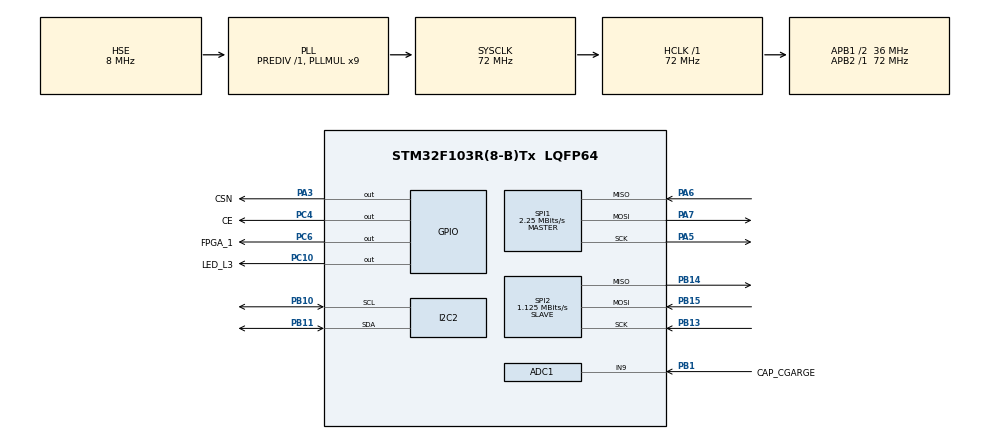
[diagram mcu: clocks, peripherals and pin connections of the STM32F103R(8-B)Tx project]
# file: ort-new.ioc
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ADC1.Channel-8\#ChannelRegularConversion=ADC_CHANNEL_9
ADC1.NbrOfConversionFlag=1
ADC1.Rank-8\#ChannelRegularConversion=1
ADC1.SamplingTime-8\#ChannelRegularConversion=ADC_SAMPLETIME_1CYCLE_5
ADC1.master=1
I2C2.I2C_Mode=I2C_Fast
Mcu.Family=STM32F1
Mcu.Name=STM32F103R(8-B)Tx
Mcu.Package=LQFP64
NVIC.ADC1_2_IRQn=true\:0\:0\:false\:false\:true\:true\:true
NVIC.PriorityGroup=NVIC_PRIORITYGROUP_4
PA13.Mode=Serial_Wire
PA13.Signal=SYS_JTMS-SWDIO
PA14.Mode=Serial_Wire
PA14.Signal=SYS_JTCK-SWCLK
PA3.GPIO_Label=CSN
PA3.Signal=GPIO_Output
PA5.Mode=Full_Duplex_Master
PA5.Signal=SPI1_SCK
PA6.Mode=Full_Duplex_Master
PA6.Signal=SPI1_MISO
PA7.Mode=Full_Duplex_Master
PA7.Signal=SPI1_MOSI
PB1.GPIO_Label=CAP_CGARGE
PB1.Signal=ADCx_IN9
PB10.Mode=I2C
PB10.Signal=I2C2_SCL
PB11.Mode=I2C
PB11.Signal=I2C2_SDA
PB13.Mode=Full_Duplex_Slave
PB13.Signal=SPI2_SCK
PB14.Mode=Full_Duplex_Slave
PB14.Signal=SPI2_MISO
PB15.Mode=Full_Duplex_Slave
PB15.Signal=SPI2_MOSI
PC10.GPIO_Label=LED_L3
PC10.Signal=GPIO_Output
PC14-OSC32_IN.Mode=LSE-External-Oscillator
PC14-OSC32_IN.Signal=RCC_OSC32_IN
PC15-OSC32_OUT.Mode=LSE-External-Oscillator
PC15-OSC32_OUT.Signal=RCC_OSC32_OUT
PC4.GPIO_Label=CE
PC4.Signal=GPIO_Output
PC6.GPIO_Label=FPGA_1
PC6.Signal=GPIO_Output
PD0-OSC_IN.Mode=HSE-External-Oscillator
PD0-OSC_IN.Signal=RCC_OSC_IN
PD1-OSC_OUT.Mode=HSE-External-Oscillator
PD1-OSC_OUT.Signal=RCC_OSC_OUT
ProjectManager.HeapSize=0x200
ProjectManager.StackSize=0x400
ProjectManager.TargetToolchain=MDK-ARM V5
RCC.ADCPresc=RCC_ADCPCLK2_DIV6
RCC.AHBFreq_Value=72000000
RCC.APB1CLKDivider=RCC_HCLK_DIV2
RCC.APB1Freq_Value=36000000
RCC.APB1TimFreq_Value=72000000
RCC.APB2Freq_Value=72000000
RCC.APB2TimFreq_Value=72000000
RCC.HCLKFreq_Value=72000000
RCC.PLLMUL=RCC_PLL_MUL9
RCC.PLLSourceVirtual=RCC_PLLSOURCE_HSE
RCC.PREFETCH_ENABLE=1
RCC.SYSCLKFreq_VALUE=72000000
RCC.SYSCLKSource=RCC_SYSCLKSOURCE_PLLCLK
RCC.TimSys_Div=SYSTICK_CLKSOURCE_HCLK_DIV8
RCC.USBFreq_Value=72000000
SH.ADCx_IN9.0=ADC1_IN9,IN9
SPI1.BaudRatePrescaler=SPI_BAUDRATEPRESCALER_32
SPI1.CalculateBaudRate=2.25 MBits/s
SPI1.Direction=SPI_DIRECTION_2LINES
SPI1.Mode=SPI_MODE_MASTER
SPI1.VirtualType=VM_MASTER
SPI2.BaudRatePrescaler=SPI_BAUDRATEPRESCALER_32
SPI2.CRCCalculation=SPI_CRCCALCULATION_DISABLE
SPI2.CalculateBaudRate=1.125 MBits/s
SPI2.DataSize=SPI_DATASIZE_8BIT
SPI2.Direction=SPI_DIRECTION_2LINES
SPI2.Mode=SPI_MODE_SLAVE
SPI2.VirtualType=VM_SLAVE
board=custom

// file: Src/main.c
/* USER CODE BEGIN Header */
/**
  ******************************************************************************
  * @file           : main.c
  * @brief          : Main program body
  ******************************************************************************
  * @attention
  *
  * <h2><center>&copy; Copyright (c) 2020 STMicroelectronics.
  * All rights reserved.</center></h2>
  *
  * This software component is licensed by ST under BSD 3-Clause license,
  * the "License"; You may not use this file except in compliance with the
  * License. You may obtain a copy of the License at:
  *                        opensource.org/licenses/BSD-3-Clause
  *
  ******************************************************************************
  */
/* USER CODE END Header */

#include "main.h"
#include "adc.h"
#include "i2c.h"
#include "spi.h"
#include "gpio.h"

/* USER CODE BEGIN Includes */
#include "ort.h"
/* USER CODE END Includes */

void SystemClock_Config(void);

/* USER CODE BEGIN 0 */

void HAL_SPI_RxCpltCallback(SPI_HandleTypeDef *hspi)
{
	if(hspi->Instance==SPI2)
	{
		HAL_SPI_Receive_IT(hspi,(uint8_t*)recive_data_arm_to_fpga,2);
	}
}
/* USER CODE END 0 */

int main(void)
{

  /* MCU Configuration--------------------------------------------------------*/

  /* Reset of all peripherals, Initializes the Flash interface and the Systick. */
  HAL_Init();

  /* Configure the system clock */
  SystemClock_Config();

  /* Initialize all configured peripherals */
  MX_GPIO_Init();
  MX_ADC1_Init();
  MX_I2C2_Init();
  MX_SPI1_Init();
  MX_SPI2_Init();
  /* USER CODE BEGIN 2 */
	setup();
	HAL_Delay(100);
	loop();
  /* USER CODE END 2 */

  /* Infinite loop */
  while (1)
  {

  }
}

void SystemClock_Config(void)
{
  RCC_OscInitTypeDef RCC_OscInitStruct = {0};
  RCC_ClkInitTypeDef RCC_ClkInitStruct = {0};
  RCC_PeriphCLKInitTypeDef PeriphClkInit = {0};

  /** Initializes the CPU, AHB and APB busses clocks
  */
  RCC_OscInitStruct.OscillatorType = RCC_OSCILLATORTYPE_HSE;
  RCC_OscInitStruct.HSEState = RCC_HSE_ON;
  RCC_OscInitStruct.HSEPredivValue = RCC_HSE_PREDIV_DIV1;
  RCC_OscInitStruct.HSIState = RCC_HSI_ON;
  RCC_OscInitStruct.PLL.PLLState = RCC_PLL_ON;
  RCC_OscInitStruct.PLL.PLLSource = RCC_PLLSOURCE_HSE;
  RCC_OscInitStruct.PLL.PLLMUL = RCC_PLL_MUL9;
  if (HAL_RCC_OscConfig(&RCC_OscInitStruct) != HAL_OK)
  {
    Error_Handler();
  }
  /** Initializes the CPU, AHB and APB busses clocks
  */
  RCC_ClkInitStruct.ClockType = RCC_CLOCKTYPE_HCLK|RCC_CLOCKTYPE_SYSCLK
                              |RCC_CLOCKTYPE_PCLK1|RCC_CLOCKTYPE_PCLK2;
  RCC_ClkInitStruct.SYSCLKSource = RCC_SYSCLKSOURCE_PLLCLK;
  RCC_ClkInitStruct.AHBCLKDivider = RCC_SYSCLK_DIV1;
  RCC_ClkInitStruct.APB1CLKDivider = RCC_HCLK_DIV2;
  RCC_ClkInitStruct.APB2CLKDivider = RCC_HCLK_DIV1;

  if (HAL_RCC_ClockConfig(&RCC_ClkInitStruct, FLASH_LATENCY_2) != HAL_OK)
  {
    Error_Handler();
  }
  PeriphClkInit.PeriphClockSelection = RCC_PERIPHCLK_ADC;
  PeriphClkInit.AdcClockSelection = RCC_ADCPCLK2_DIV6;
  if (HAL_RCCEx_PeriphCLKConfig(&PeriphClkInit) != HAL_OK)
  {
    Error_Handler();
  }
}

void Error_Handler(void)
{
}

/************************ (C) COPYRIGHT STMicroelectronics *****END OF FILE****/
